# WKUP_PSC0 register map
Vendor: Texas Instruments
Peripheral module from a debugger description file (folder J722S).
Registers are 32-bit, read-only, reset 0x0 unless marked. A register's access mark holds for its fields unless they carry their own. Offsets are as the file gives them; lines under a group give offsets from that group; [hi:lo] are bit positions; {n}, {i} and the like mark numbered series; 'fields as' and 'values as' point back to an identical list; <NAME> marks a mode.

## WKUP_PSC0
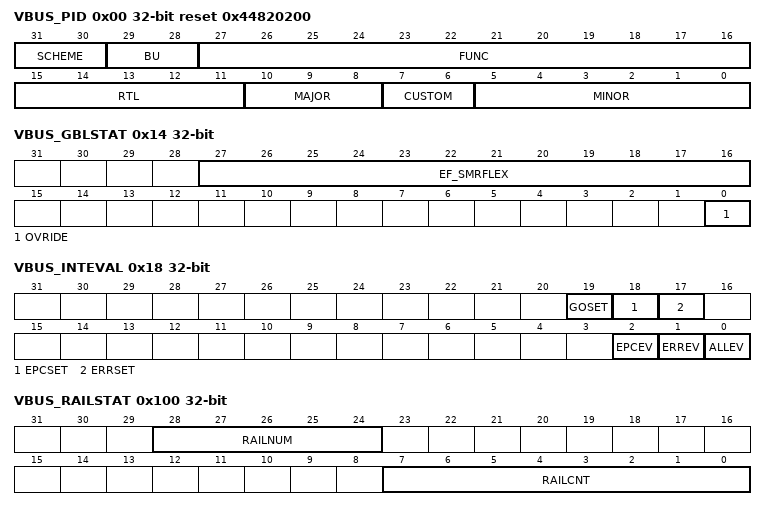
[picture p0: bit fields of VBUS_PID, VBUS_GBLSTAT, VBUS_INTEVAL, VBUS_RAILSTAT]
0x00 VBUS_PID reset 0x44820200 — The peripheral identification register is a constant register that contains the ID and ID revision number for that module. The PID stores version information used to identify the module. All bits within this register are read-only (writes have no effect) meaning that the values within this register should be hard-coded with the appropriate values and must not change from their hard-coded values.
  [31:30] SCHEME — PID register scheme
  [29:28] BU — Business Unit
  [27:16] FUNC — Module ID
  [15:11] RTL — RTL revision. Will vary depending on release
  [10:8] MAJOR — Major revision
  [7:6] CUSTOM
  [5:0] MINOR — Minor revision
0x10 VBUS_GBLCTL — This register contains global control to PSC.
  [15:8] IO_ANA_CTL — General purpose IO/Analog PowerDown control. Directly drives io_ana_pdctl_po[7:0] outputs.
0x14 VBUS_GBLSTAT — This register shows the PSC global status.
  [27:16] EF_SMRFLEX — Smart reflex class0 bits
  [0] OVRIDE — PSC Override Status
0x18 VBUS_INTEVAL wo — This register has no storage. Read from this register returns 0.
  [19] GOSET — GOSTAT Interrupt Set
  [18] EPCSET — External Power Control Interrupt Set
  [17] ERRSET — Combined Interrupt Set
  [2] EPCEV — External Power Control Interrupt Set
  [1] ERREV — Re_evaluate Error Interrupt
  [0] ALLEV — Re_evaluate combined PSC interrupt
0x40 VBUS_MERRPR — This register records pending error conditions for all modules. Each bit represents one module (index 0 for modules 0-31, index 1 for modules 32-63, etc.).
  [31:0] M — Records pending error conditions. Each bit n represents a module.
0x50 VBUS_MERRCR access not given — This register has no storage. Read from this register returns 0. Each bit represents one module (index 0 for modules 0-31, index 1 for modules 32-63, etc.).
  [31:0] M — Write of 1 clears the corresponding MERRPR bit. (access W1TC)
0x60 VBUS_PERRPR — This register records pending error conditions for each power domain. Each bit represents one domain (index 0 for domains 0-31, index 1 for domains 32-63, etc.).
  [31:0] P — Power Domain n Error Condition. Each bit n represents a power domain.
0x68 VBUS_PERRCR access not given — This register has no storage. Read from this register returns 0. Each bit represents one domain (index 0 for domains 0-31, index 1 for domains 32-63, etc.).
  [31:0] P — Write of 1 clears the corresponding PERRPR bit. (access W1TC)
0x70 VBUS_EPCPR — This register records pending external power control conditions. Each bit represents one domain (index 0 for domains 0-31, index 1 for domains 32-63, etc.).
  [31:0] EPC — External Power Control Intervention Request for Power Domain n
0x78 VBUS_EPCCR access not given — This register has no storage. Read from this register returns 0. Each bit represents one domain (index 0 for domains 0-31, index 1 for domains 32-63, etc.).
  [31:0] EPC — Write of 1 clears the corresponding EPCPR bit (access W1TC)
0x100 VBUS_RAILSTAT — This register is a read-only and shows the current rail requestor whose request is being granted and the current value of the counter associated with this requestor.
  [28:24] RAILNUM — Indicates Current Rail Requestor being processed by GPSC
  [7:0] RAILCNT — Indicates the current rail counter value
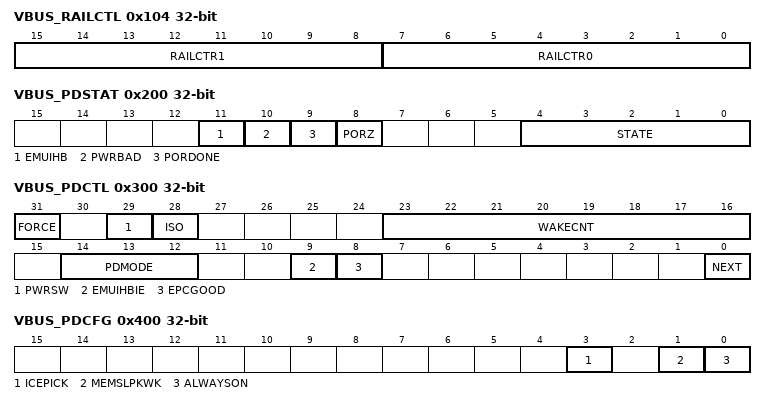
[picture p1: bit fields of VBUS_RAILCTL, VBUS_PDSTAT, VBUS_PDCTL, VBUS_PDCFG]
0x104 VBUS_RAILCTL rw — This register is user programmable. It holds the counter values for rail counter. User can select one of the two counter values to be used for each power domain (see RAILSEL register).
  [15:8] RAILCTR1 — Rail Counter Value 1
  [7:0] RAILCTR0 — Rail Counter Value 0
0x108 VBUS_RAILSEL rw — User can use this register to select the counter value (RAILCTL) for each power domain.
  [31:0] P — Rail Counter Select for Power Domain
0x120 VBUS_PTCMD access not given — This is a pseudo-command register with no actual storage. Reads return 0. One bit for each power domain (index 0 for domains 0-31, index 1 for domains 32-63, etc.).
  [31:0] GO — Power Domain n GO Transition (access W1TS)
0x128 VBUS_PTSTAT — This is a status register. One bit for each power domain (index 0 for domains 0-31, index 1 for domains 32-63, etc.).
  [31:0] GOSTAT — Power Domain n Transition Command Status
0x200 VBUS_PDSTAT — This is a status register. One register per power domain. Each register contains the status for the given power domain.
  [11] EMUIHB — Emulation Alters Domain State
  [10] PWRBAD — Power Bad error
  [9] PORDONE — POR Done Input Status
  [8] PORZ — PORz output actual status
  [4:0] STATE — Current Power Domain State
0x300 VBUS_PDCTL rw — This is a control register. One register per power domain.
  [31] FORCE — Force Bit
  [29] PWRSW — Power shorting Switch Control
  [28] ISO — Isolation Cell control
  [23:16] WAKECNT — RAM wake count delay value
  [14:12] PDMODE — Power Down mode
  [9] EMUIHBIE — Emulation alters domain state
  [8] EPCGOOD — External Power Control Power Good Indication
  [0] NEXT — User_Desired Next Power Domain State
0x400 VBUS_PDCFG — This is a status register. It shows PSC settings for easy debug.
  [3] ICEPICK — Icepick support
  [1] MEMSLPKWK — Memory sleep-wake domain
  [0] ALWAYSON — Always on power domain
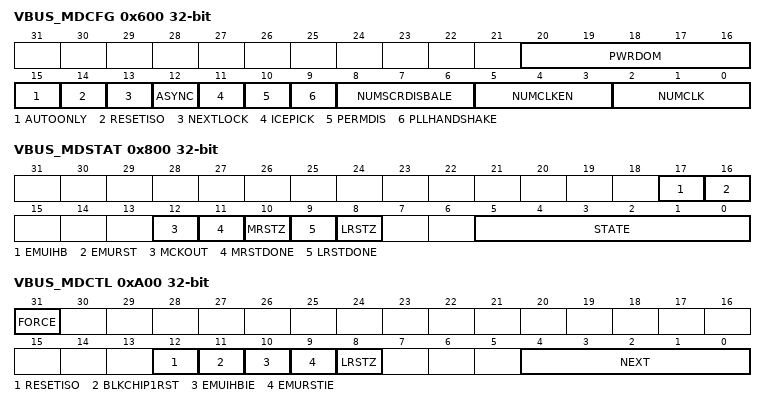
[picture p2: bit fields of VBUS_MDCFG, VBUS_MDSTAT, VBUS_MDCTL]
0x600 VBUS_MDCFG — This is a constant register showing some PSC settings for easy debug. This register is read only.
  [20:16] PWRDOM — Indicates which power domain this module belongs to
  [15] AUTOONLY — 0: This LPSC supports all modes, 1: This LPSC supports Enable, AutoSleep or AutoWake only
  [14] RESETISO — 0: This LPSC does not support Reset Isolation, 1: This LPSC supports Reset Isolation
  [13] NEXTLOCK — 0: MDCTL.NEXT field is writable, 1: MDCTL.NEXT field is locked
  [12] ASYNC — Async Lpsc
  [11] ICEPICK — IcePick support
  [10] PERMDIS — Permanently disable
  [9] PLLHANDSHAKE — RTL parameter PLL_HANDSHAKE
  [8:6] NUMSCRDISBALE — Number of PWR_SCR_DISABLE interfaces required on LPSC
  [5:3] NUMCLKEN — Number of PWR_CLK_EN interfaces required on LPSC
  [2:0] NUMCLK — Number of PWR_CLKSTOP interfaces required on LPSC
0x800 VBUS_MDSTAT — This register shows the status of each module. Requires one register per module on the device.
  [17] EMUIHB — Emulation Alters Module State. Inhibits Module Inactive or Force Module Active.
  [16] EMURST — Emulation Alters Reset
  [12] MCKOUT — Actual modclk output to module
  [11] MRSTDONE — Module reset initialization done status
  [10] MRSTZ — Module reset actual status
  [9] LRSTDONE — Module local reset initialization done status
  [8] LRSTZ — Module local reset actual status
  [5:0] STATE — These bits indicate the current module state
0xA00 VBUS_MDCTL rw — This register provides specific control for the individual module. One register per module on the device.
  [31] FORCE — Force Bit
  [12] RESETISO — Reset Isolation
  [11] BLKCHIP1RST — Block Chip_1_Reset
  [10] EMUIHBIE — Emulation Alters Module State. Inhibits Module Inactive or Force Module Active.
  [9] EMURSTIE — Emulation Alter Reset Interrupt Enable
  [8] LRSTZ — Module local reset control
  [4:0] NEXT — Module Next State
